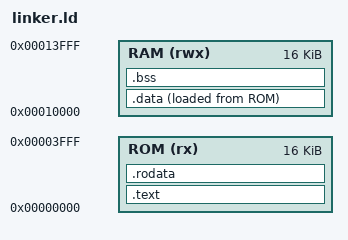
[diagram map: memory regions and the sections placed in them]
ENTRY(_start)

MEMORY
{
    ROM (rx)  : ORIGIN = 0x00000000, LENGTH = 16K
    RAM (rwx) : ORIGIN = 0x00010000, LENGTH = 16K
}

SECTIONS
{
    .text :
    {
        *(.text.init)
        *(.text*)
    } > ROM

    .rodata :
    {
        *(.rodata*)
    } > ROM

    .data :
    {
        *(.data*)
    } > RAM AT > ROM

    .bss :
    {
        _bss_start = .;
        *(.bss*)
        *(COMMON)
        _bss_end = .;
    } > RAM

    _stack_top = ORIGIN(RAM) + LENGTH(RAM);
}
